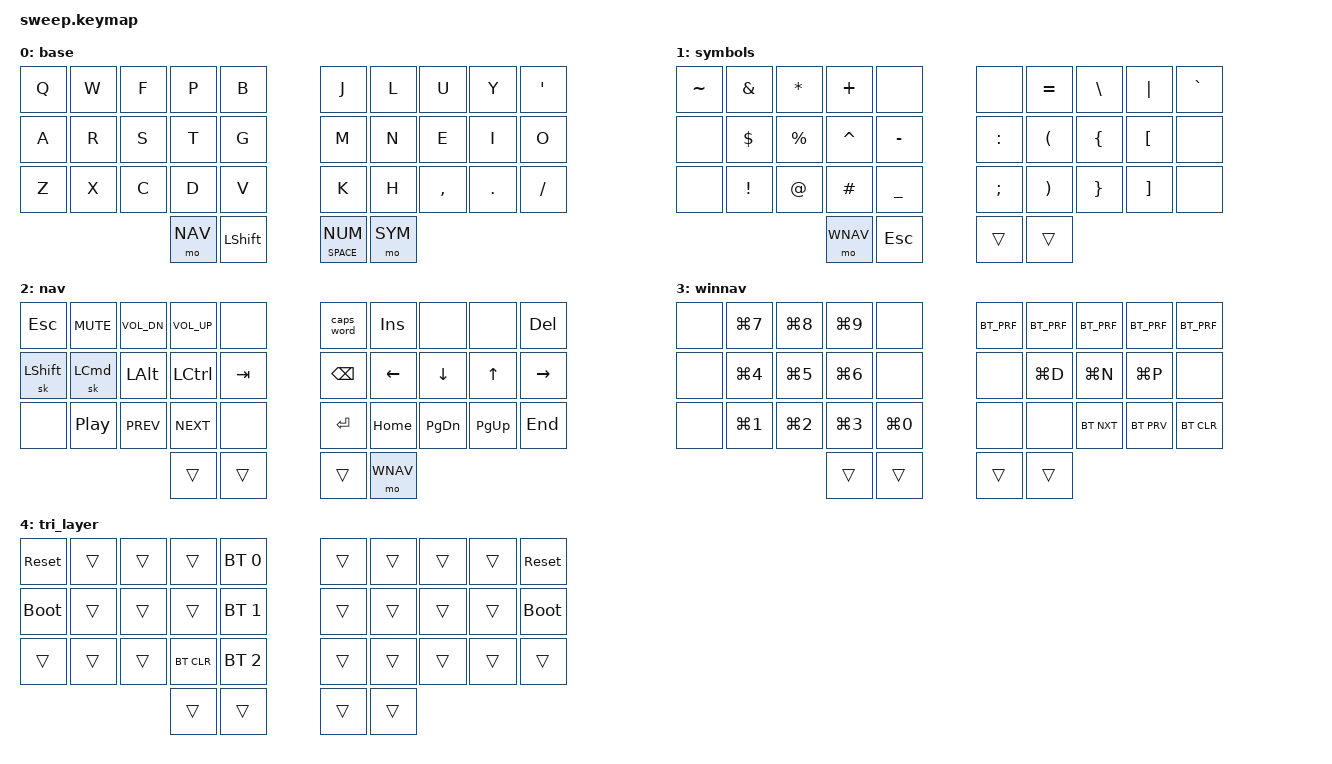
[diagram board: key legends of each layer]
// Copyright (c) 2022 The ZMK Contributors
// SPDX-License-Identifier: MIT

#include <behaviors.dtsi>
#include <dt-bindings/zmk/keys.h>
#include <dt-bindings/zmk/bt.h>

#define BASE 0
#define SYM 1
#define NAV 2
#define WNAV 3
#define NUM 5
#define FUN 6
#define MODS 7
#define FRA 8
#define VOL_DN C_VOL_DN
#define VOL_UP C_VOL_UP

#define SPC_NUM &lt SPACE NUM

#define BT_PRF(num) &bt BT_SEL num


&sk {
  release-after-ms = <2000>;
}

/ {
    behaviors {
        ht: hold_tap {
            compatible = "zmk,behavior-hold-tap";
            #binding-cells = <2>;
            flavor = "tap-preferred";
            tapping-term-ms = <220>;
            quick-tap-ms = <150>;
            require-prior-idle-ms = <100>;
            bindings = <&kp>, <&kp>;
        };
    };

    conditional_layers {
        compatible = "zmk,conditional-layers";
        tri_layer {
            if-layers = <SYM NAV>;
            then-layer = <WNAV>;
        };
    };

    keymap {
        compatible = "zmk,keymap";
        base {
            bindings = <
        //╭──────────┬──────────┬──────────┬──────────┬──────────╮   ╭──────────┬──────────┬──────────┬──────────┬──────────╮
        //│  Q       │  W       │  F       │  P       │  B       │   │  J       │  L       │  U       │  Y       │  '       │
            &kp Q      &kp W      &kp F      &kp P      &kp B          &kp J      &kp L      &kp U      &kp Y      &kp SQT
        //├──────────┼──────────┼──────────┼──────────┼──────────┤   ├──────────┼──────────┼──────────┼──────────┼──────────┤
        //│  A       │  R       │  S       │  T       │  G       │   │  M       │  N       │  E       │  I       │  O       │
            &kp A      &kp R      &kp S      &kp T      &kp G          &kp M      &kp N      &kp E      &kp I      &kp O
        //├──────────┼──────────┼──────────┼──────────┼──────────┤   ├──────────┼──────────┼──────────┼──────────┼──────────┤
        //│  Z       │  X       │  C       │  D       │  V       │   │  K       │  H       │ , <      │ . >      │ / ?      │
            &kp Z      &kp X      &kp C      &kp D      &kp V          &kp K      &kp H      &kp COMMA  &kp DOT    &kp FSLH
        //╰──────────┴──────────┴──────────┼──────────┼──────────┤   ├──────────┼──────────┼──────────┴──────────┴──────────╯
                                            &mo NAV     &kp LSHFT      SPC_NUM    &mo SYM
        //                                 ╰──────────┴──────────╯   ╰──────────┴──────────╯
            >;
        };

        symbols {
            bindings = <
        //╭──────────┬──────────┬──────────┬──────────┬──────────╮   ╭──────────┬──────────┬──────────┬──────────┬──────────╮
        //│  ~       │  &       │  *       │  +       │          │   │          │  =       │  \       │  |       │  `       │
            &kp TILDE  &kp AMPS   &kp STAR   &kp PLUS   &none          &none      &kp EQUAL  &kp BSLH   &kp PIPE   &kp GRAVE
        //├──────────┼──────────┼──────────┼──────────┼──────────┤   ├──────────┼──────────┼──────────┼──────────┼──────────┤
        //│          │  $       │  %       │  ^       │  -       │   │  :       │  (       │  {       │  [       │          │
            &none      &kp DLLR   &kp PRCNT  &kp CARET  &kp MINUS      &kp COLN   &kp LPAR   &kp LBRC   &kp LBKT   &none
        //├──────────┼──────────┼──────────┼──────────┼──────────┤   ├──────────┼──────────┼──────────┼──────────┼──────────┤
        //│          │  !       │  @       │  #       │  _       │   │  ;       │  )       │  }       │  ]       │          │
            &none      &kp EXCL   &kp AT     &kp HASH   &kp UNDER      &kp SEMI   &kp RPAR   &kp RBRC   &kp RBKT   &none
        //╰──────────┴──────────┴──────────┼──────────┼──────────┤   ├──────────┼──────────┼──────────┴──────────┴──────────╯
                                             &mo WNAV   &kp ESC        &trans     &trans
        //                                 ╰──────────┴──────────╯   ╰──────────┴──────────╯
            >;
        };

        nav {
            bindings = <
        //╭──────────┬──────────┬──────────┬──────────┬──────────╮   ╭──────────┬──────────┬──────────┬──────────┬──────────╮
        //│  ESCAPE  │  MUTE    │ VOL DOWN │  VOL UP  │          │   │ CAPS WORD│  INSERT  │          │          │  DEL     │
            &kp ESC   &kp C_MUTE &kp VOL_DN &kp VOL_UP  &none         &caps_word  &kp INS    &none      &none      &kp DEL
        //├──────────┼──────────┼──────────┼──────────┼──────────┤   ├──────────┼──────────┼──────────┼──────────┼──────────┤
        //│  SHIFT   │  CMD     │  ALT     │  CTRL    │  TAB     │   │ BACKSPACE│  LEFT    │  DOWN    │  UP      │  RIGHT   │
            &sk LSHFT  &sk LCMD   &kp LALT   &kp LCTRL  &kp TAB        &kp BSPC   &kp LEFT   &kp DOWN   &kp UP     &kp RIGHT
        //├──────────┼──────────┼──────────┼──────────┼──────────┤   ├──────────┼──────────┼──────────┼──────────┼──────────┤
        //│          │  PLAY    │ PREVIOUS │  NEXT    │          │   │  ENTER   │  HOME    │  PG DOWN │  PG UP   │  END     │
            &none      &kp C_PP  &kp C_PREV &kp C_NEXT  &none          &kp ENTER  &kp HOME   &kp PG_DN  &kp PG_UP  &kp END
        //╰──────────┴──────────┴──────────┼──────────┼──────────┤   ├──────────┼──────────┼──────────┴──────────┴──────────╯
                                             &trans     &trans         &trans     &mo WNAV
        //                                 ╰──────────┴──────────╯   ╰──────────┴──────────╯
            >;
        };

        winnav {
            bindings = <
        //╭──────────┬──────────┬──────────┬──────────┬──────────╮   ╭──────────┬──────────┬──────────┬──────────┬──────────╮
        //│          │          │          │          │          │   │          │          │          │          │          │
            &none     &kp LG(N7) &kp LG(N8) &kp LG(N9)  &none          BT_PRF 0   BT_PRF 1   BT_PRF 2   BT_PRF 3   BT_PRF 4
        //├──────────┼──────────┼──────────┼──────────┼──────────┤   ├──────────┼──────────┼──────────┼──────────┼──────────┤
        //│          │          │          │          │          │   │          │          │          │          │          │
            &none     &kp LG(N4) &kp LG(N5) &kp LG(N6)  &none          &none      &kp LG(D)  &kp LG(N)  &kp LG(P)  &none
        //├──────────┼──────────┼──────────┼──────────┼──────────┤   ├──────────┼──────────┼──────────┼──────────┼──────────┤
        //│          │          │          │          │          │   │          │          │          │          │          │
            &none     &kp LG(N1) &kp LG(N2) &kp LG(N3) &kp LG(N0)      &none      &none     &bt BT_NXT &bt BT_PRV &bt BT_CLR
        //╰──────────┴──────────┴──────────┼──────────┼──────────┤   ├──────────┼──────────┼──────────┴──────────┴──────────╯
                                             &trans     &trans         &trans     &trans
        //                                 ╰──────────┴──────────╯   ╰──────────┴──────────╯
            >;
        };

        tri_layer {
            bindings = <
        //╭──────────┬──────────┬──────────┬──────────┬──────────╮   ╭──────────┬──────────┬──────────┬──────────┬──────────╮
        //│ RESET    │          │          │          │PROFILE 0 │   │          │          │          │          │  RESET   │
           &sys_reset  &trans     &trans     &trans    &bt BT_SEL 0    &trans     &trans     &trans     &trans    &sys_reset
        //├──────────┼──────────┼──────────┼──────────┼──────────┤   ├──────────┼──────────┼──────────┼──────────┼──────────┤
        //│BOOTLOADER│          │          │          │PROFILE 1 │   │          │          │          │          │BOOTLOADER│
          &bootloader  &trans     &trans     &trans    &bt BT_SEL 1    &trans     &trans     &trans     &trans    &bootloader
        //├──────────┼──────────┼──────────┼──────────┼──────────┤   ├──────────┼──────────┼──────────┼──────────┼──────────┤
        //│          │          │          │ CLEAR BT │PROFILE 2 │   │          │          │          │          │          │
            &trans     &trans     &trans    &bt BT_CLR &bt BT_SEL 2    &trans     &trans     &trans     &trans     &trans
        //╰──────────┴──────────┴──────────┼──────────┼──────────┤   ├──────────┼──────────┼──────────┴──────────┴──────────╯
                                             &trans     &trans         &trans     &trans
        //                                 ╰──────────┴──────────╯   ╰──────────┴──────────╯
            >;
        };
    };
};
